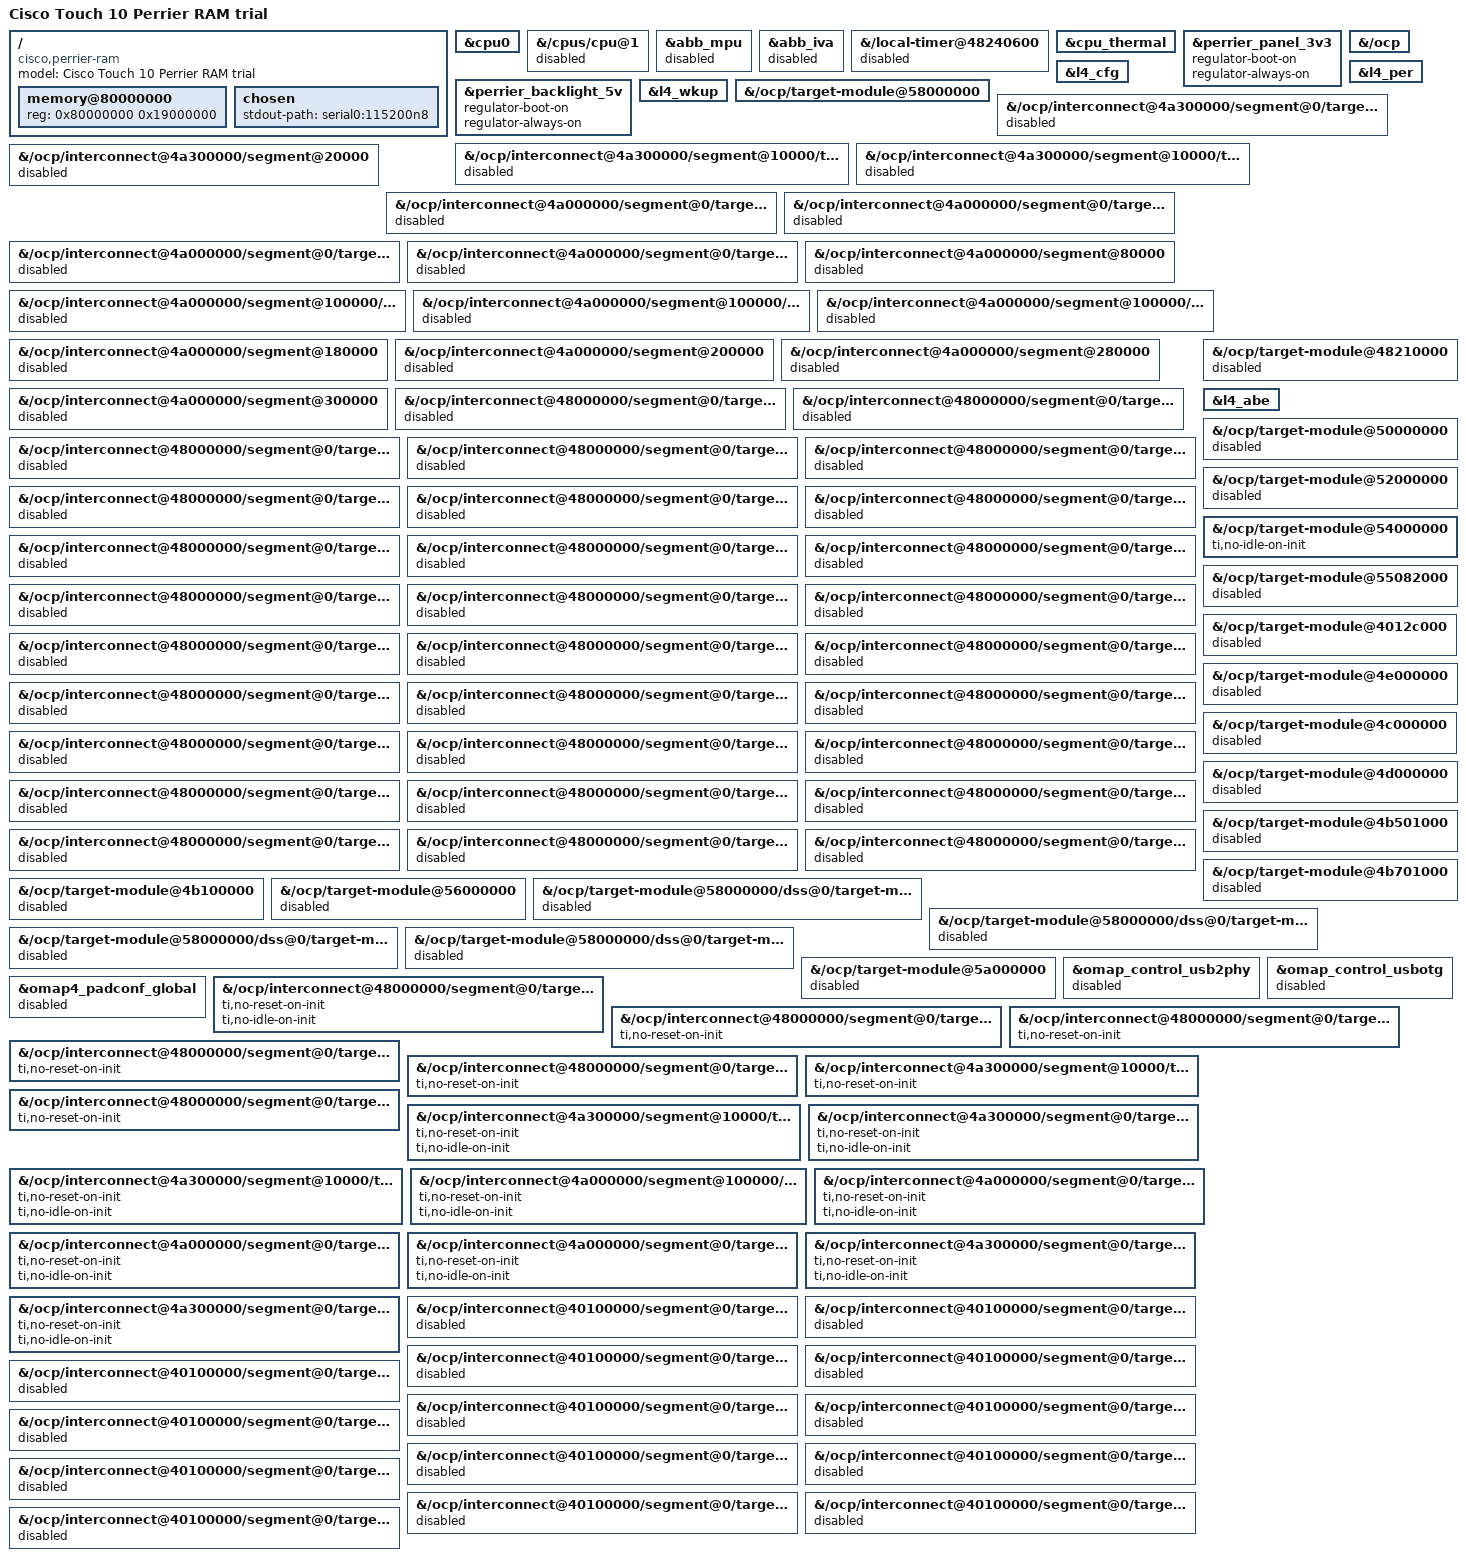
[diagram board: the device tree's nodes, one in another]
// SPDX-License-Identifier: GPL-2.0-only
// RAM-only development policy on the normal OMAP interconnect hierarchy.
/dts-v1/;
#include "omap4460.dtsi"
#include "omap4-cisco-perrier.dtsi"

/ {
	model = "Cisco Touch 10 Perrier RAM trial";
	compatible = "cisco,perrier-ram", "ti,omap4460", "ti,omap4";
	memory@80000000 {
		device_type = "memory";
		reg = <0x80000000 0x19000000>;
	};
	chosen {
		#address-cells = <1>;
		#size-cells = <1>;
		ranges;
		stdout-path = "serial0:115200n8";
	};
};

&cpu0 { /delete-property/ operating-points; };
&{/cpus/cpu@1} { status = "disabled"; };
&abb_mpu { status = "disabled"; };
&abb_iva { status = "disabled"; };
&{/local-timer@48240600} { status = "disabled"; };
&cpu_thermal { /delete-node/ cooling-maps; };

&perrier_panel_3v3 {
	regulator-boot-on;
	regulator-always-on;
};
&perrier_backlight_5v {
	regulator-boot-on;
	regulator-always-on;
};

// Retain the existing RAM power policy while migrating topology. Runtime
// power-domain integration is a separate step; no PMIC driver is added.
&{/ocp} { /delete-property/ power-domains; };
&l4_cfg { /delete-property/ power-domains; };
&l4_per { /delete-property/ power-domains; };
&l4_wkup { /delete-property/ power-domains; };
&{/ocp/target-module@58000000} { /delete-property/ power-domains; };

// Do not probe unused peripherals merely because their parent buses are on.
&{/ocp/interconnect@4a300000/segment@0/target-module@c000} { status = "disabled"; };
&{/ocp/interconnect@4a300000/segment@10000/target-module@0} { status = "disabled"; };
&{/ocp/interconnect@4a300000/segment@10000/target-module@e000} { status = "disabled"; };
&{/ocp/interconnect@4a300000/segment@20000} { status = "disabled"; };
&{/ocp/interconnect@4a000000/segment@0/target-module@58000} { status = "disabled"; };
&{/ocp/interconnect@4a000000/segment@0/target-module@5e000} { status = "disabled"; };
&{/ocp/interconnect@4a000000/segment@0/target-module@62000} { status = "disabled"; };
&{/ocp/interconnect@4a000000/segment@0/target-module@66000} { status = "disabled"; };
&{/ocp/interconnect@4a000000/segment@80000} { status = "disabled"; };
&{/ocp/interconnect@4a000000/segment@100000/target-module@2000} { status = "disabled"; };
&{/ocp/interconnect@4a000000/segment@100000/target-module@8000} { status = "disabled"; };
&{/ocp/interconnect@4a000000/segment@100000/target-module@a000} { status = "disabled"; };
&{/ocp/interconnect@4a000000/segment@180000} { status = "disabled"; };
&{/ocp/interconnect@4a000000/segment@200000} { status = "disabled"; };
&{/ocp/interconnect@4a000000/segment@280000} { status = "disabled"; };
&{/ocp/interconnect@4a000000/segment@300000} { status = "disabled"; };
&{/ocp/interconnect@48000000/segment@0/target-module@32000} { status = "disabled"; };
&{/ocp/interconnect@48000000/segment@0/target-module@34000} { status = "disabled"; };
&{/ocp/interconnect@48000000/segment@0/target-module@36000} { status = "disabled"; };
&{/ocp/interconnect@48000000/segment@0/target-module@3e000} { status = "disabled"; };
&{/ocp/interconnect@48000000/segment@0/target-module@40000} { status = "disabled"; };
&{/ocp/interconnect@48000000/segment@0/target-module@55000} { status = "disabled"; };
&{/ocp/interconnect@48000000/segment@0/target-module@6a000} { status = "disabled"; };
&{/ocp/interconnect@48000000/segment@0/target-module@6c000} { status = "disabled"; };
&{/ocp/interconnect@48000000/segment@0/target-module@6e000} { status = "disabled"; };
&{/ocp/interconnect@48000000/segment@0/target-module@76000} { status = "disabled"; };
&{/ocp/interconnect@48000000/segment@0/target-module@78000} { status = "disabled"; };
&{/ocp/interconnect@48000000/segment@0/target-module@88000} { status = "disabled"; };
&{/ocp/interconnect@48000000/segment@0/target-module@90000} { status = "disabled"; };
&{/ocp/interconnect@48000000/segment@0/target-module@96000} { status = "disabled"; };
&{/ocp/interconnect@48000000/segment@0/target-module@98000} { status = "disabled"; };
&{/ocp/interconnect@48000000/segment@0/target-module@9a000} { status = "disabled"; };
&{/ocp/interconnect@48000000/segment@0/target-module@9c000} { status = "disabled"; };
&{/ocp/interconnect@48000000/segment@0/target-module@9e000} { status = "disabled"; };
&{/ocp/interconnect@48000000/segment@0/target-module@a2000} { status = "disabled"; };
&{/ocp/interconnect@48000000/segment@0/target-module@a4000} { status = "disabled"; };
&{/ocp/interconnect@48000000/segment@0/target-module@a5000} { status = "disabled"; };
&{/ocp/interconnect@48000000/segment@0/target-module@a8000} { status = "disabled"; };
&{/ocp/interconnect@48000000/segment@0/target-module@ad000} { status = "disabled"; };
&{/ocp/interconnect@48000000/segment@0/target-module@b0000} { status = "disabled"; };
&{/ocp/interconnect@48000000/segment@0/target-module@b2000} { status = "disabled"; };
&{/ocp/interconnect@48000000/segment@0/target-module@b8000} { status = "disabled"; };
&{/ocp/interconnect@48000000/segment@0/target-module@ba000} { status = "disabled"; };
&{/ocp/interconnect@48000000/segment@0/target-module@d1000} { status = "disabled"; };
&{/ocp/interconnect@48000000/segment@0/target-module@d5000} { status = "disabled"; };
&{/ocp/target-module@48210000} { status = "disabled"; };
&l4_abe {
	status = "okay";
	/delete-property/ power-domains;
};
&{/ocp/target-module@50000000} { status = "disabled"; };
&{/ocp/target-module@52000000} { status = "disabled"; };
// Use the upstream OMAP4460 Cortex-A9 PMU/IRQ description. Retain the
// development power-domain policy while enabling its debug clock branch.
&{/ocp/target-module@54000000} {
	status = "okay";
	/delete-property/ power-domains;
	ti,no-idle-on-init;
};
&{/ocp/target-module@55082000} { status = "disabled"; };
&{/ocp/target-module@4012c000} { status = "disabled"; };
&{/ocp/target-module@4e000000} { status = "disabled"; };
&{/ocp/target-module@4c000000} { status = "disabled"; };
&{/ocp/target-module@4d000000} { status = "disabled"; };
&{/ocp/target-module@4b501000} { status = "disabled"; };
&{/ocp/target-module@4b701000} { status = "disabled"; };
&{/ocp/target-module@4b100000} { status = "disabled"; };
&{/ocp/target-module@56000000} { status = "disabled"; };
&{/ocp/target-module@58000000/dss@0/target-module@2000} { status = "disabled"; };
&{/ocp/target-module@58000000/dss@0/target-module@3000} { status = "disabled"; };
&{/ocp/target-module@58000000/dss@0/target-module@5000} { status = "disabled"; };
&{/ocp/target-module@58000000/dss@0/target-module@6000} { status = "disabled"; };
&{/ocp/target-module@5a000000} { status = "disabled"; };

// These unused children share enabled control/USB/display target modules.
&omap_control_usb2phy { status = "disabled"; };
&omap_control_usbotg { status = "disabled"; };
&omap4_padconf_global { status = "disabled"; };

// Preserve the working output latches and active watchdog across handoff.
&{/ocp/interconnect@48000000/segment@0/target-module@20000} {
	ti,no-reset-on-init;
	ti,no-idle-on-init;
};
&{/ocp/interconnect@48000000/segment@0/target-module@57000} {
	ti,no-reset-on-init;
};
&{/ocp/interconnect@48000000/segment@0/target-module@59000} {
	ti,no-reset-on-init;
};
&{/ocp/interconnect@48000000/segment@0/target-module@5b000} {
	ti,no-reset-on-init;
};
&{/ocp/interconnect@48000000/segment@0/target-module@5d000} {
	ti,no-reset-on-init;
};
&{/ocp/interconnect@4a300000/segment@10000/target-module@c000} {
	ti,no-reset-on-init;
};
&{/ocp/interconnect@48000000/segment@0/target-module@86000} {
	ti,no-reset-on-init;
};
&{/ocp/interconnect@4a300000/segment@10000/target-module@4000} {
	ti,no-reset-on-init;
	ti,no-idle-on-init;
};
&{/ocp/interconnect@4a300000/segment@0/target-module@4000} {
	ti,no-reset-on-init;
	ti,no-idle-on-init;
};
&{/ocp/interconnect@4a300000/segment@10000/target-module@8000} {
	ti,no-reset-on-init;
	ti,no-idle-on-init;
};
&{/ocp/interconnect@4a000000/segment@100000/target-module@0} {
	ti,no-reset-on-init;
	ti,no-idle-on-init;
};
&{/ocp/interconnect@4a000000/segment@0/target-module@2000} {
	ti,no-reset-on-init;
	ti,no-idle-on-init;
};
&{/ocp/interconnect@4a000000/segment@0/target-module@4000} {
	ti,no-reset-on-init;
	ti,no-idle-on-init;
};
&{/ocp/interconnect@4a000000/segment@0/target-module@8000} {
	ti,no-reset-on-init;
	ti,no-idle-on-init;
};
&{/ocp/interconnect@4a300000/segment@0/target-module@6000} {
	ti,no-reset-on-init;
	ti,no-idle-on-init;
};
&{/ocp/interconnect@4a300000/segment@0/target-module@a000} {
	ti,no-reset-on-init;
	ti,no-idle-on-init;
};
&{/ocp/interconnect@40100000/segment@0/target-module@22000} { status = "disabled"; };
&{/ocp/interconnect@40100000/segment@0/target-module@24000} { status = "disabled"; };
&{/ocp/interconnect@40100000/segment@0/target-module@26000} { status = "disabled"; };
&{/ocp/interconnect@40100000/segment@0/target-module@28000} { status = "disabled"; };
&{/ocp/interconnect@40100000/segment@0/target-module@2e000} { status = "disabled"; };
&{/ocp/interconnect@40100000/segment@0/target-module@30000} { status = "disabled"; };
&{/ocp/interconnect@40100000/segment@0/target-module@38000} { status = "disabled"; };
&{/ocp/interconnect@40100000/segment@0/target-module@3a000} { status = "disabled"; };
&{/ocp/interconnect@40100000/segment@0/target-module@3c000} { status = "disabled"; };
&{/ocp/interconnect@40100000/segment@0/target-module@3e000} { status = "disabled"; };
&{/ocp/interconnect@40100000/segment@0/target-module@80000} { status = "disabled"; };
&{/ocp/interconnect@40100000/segment@0/target-module@a0000} { status = "disabled"; };
&{/ocp/interconnect@40100000/segment@0/target-module@c0000} { status = "disabled"; };
&{/ocp/interconnect@40100000/segment@0/target-module@f1000} { status = "disabled"; };
